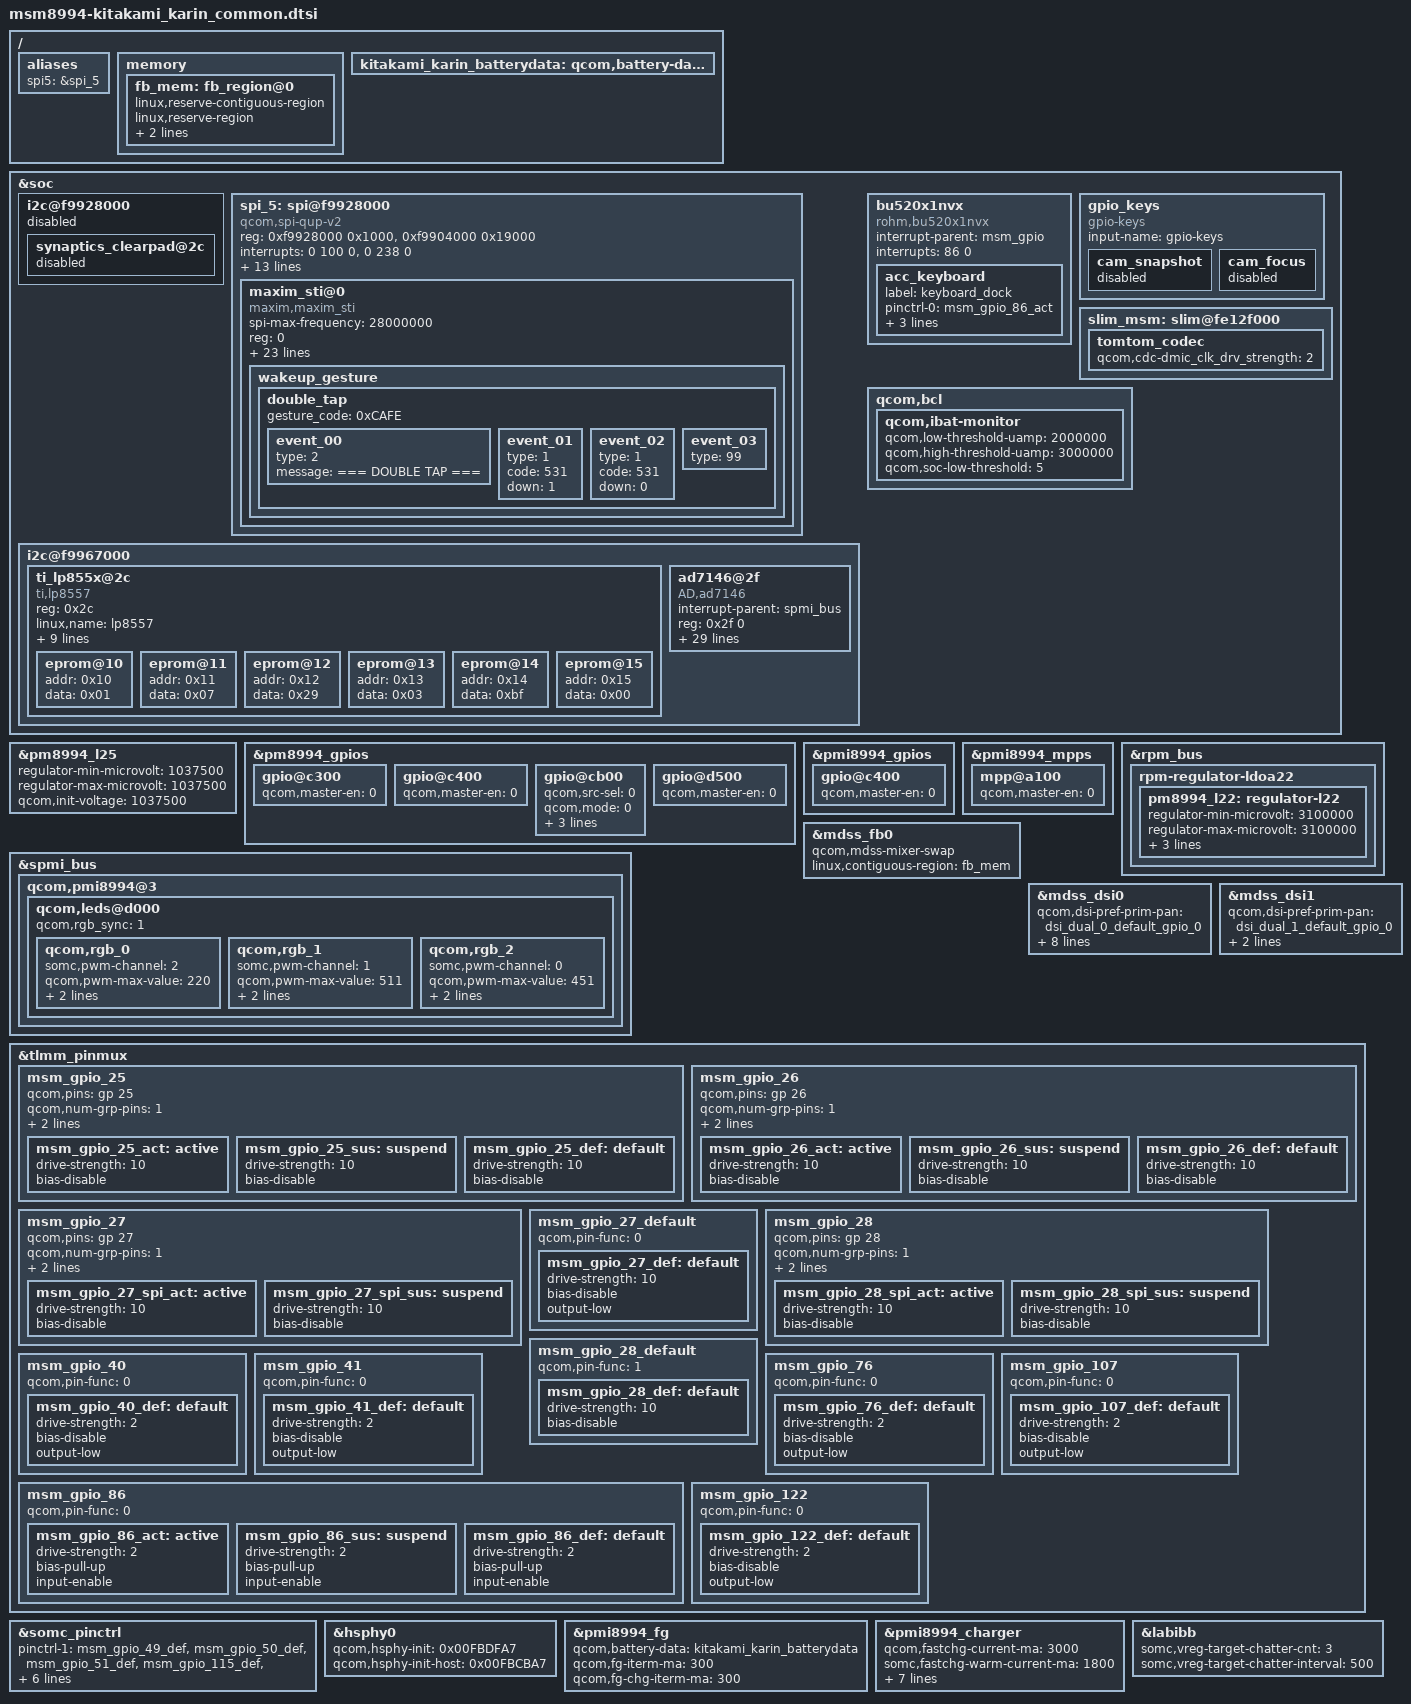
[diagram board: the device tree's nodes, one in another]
/* arch/arm/boot/dts/qcom/msm8994-kitakami_karin_common.dtsi
 *
 * This program is free software; you can redistribute it and/or modify
 * it under the terms of the GNU General Public License version 2 and
 * only version 2 as published by the Free Software Foundation.
 *
 * This program is distributed in the hope that it will be useful,
 * but WITHOUT ANY WARRANTY; without even the implied warranty of
 * MERCHANTABILITY or FITNESS FOR A PARTICULAR PURPOSE.  See the
 * GNU General Public License for more details.
 */
/*
 * Copyright (C) 2014 Sony Mobile Communications Inc.
 *
 * This program is free software; you can redistribute it and/or modify
 * it under the terms of the GNU General Public License version 2, as
 * published by the Free Software Foundation.
 */

/ {
	aliases {
		spi5 = &spi_5;
	};

	memory {

		fb_mem: fb_region@0 {
			linux,reserve-contiguous-region;
			linux,reserve-region;
			reg = <0 0x40000000 0 0x2000000>;
			label = "fb_mem";
		};
	};
};

&soc {
	i2c@f9928000 {
		status = "disabled";
		synaptics_clearpad@2c {
			status = "disabled";
		};
	};

	/* SPI : BLSP6 */
	spi_5: spi@f9928000 {
		compatible = "qcom,spi-qup-v2";
		#address-cells = <1>;
		#size-cells = <0>;
		reg-names = "spi_physical", "spi_bam_physical";
		reg = <0xf9928000 0x1000>, <0xf9904000 0x19000>;
		interrupt-names = "spi_irq", "spi_bam_irq";
		interrupts = <0 100 0>, <0 238 0>;
		spi-max-frequency = <48000000>;
		qcom,use-bam;
		qcom,ver-reg-exists;
		qcom,bam-consumer-pipe-index = <22>;
		qcom,bam-producer-pipe-index = <23>;
		qcom,master-id = <86>;

		qcom,use-pinctrl;
		pinctrl-names = "default", "sleep";
		pinctrl-0 = <&msm_gpio_25_act &msm_gpio_26_act &msm_gpio_27_spi_act &msm_gpio_28_spi_act>;
		pinctrl-1 = <&msm_gpio_25_sus &msm_gpio_26_sus &msm_gpio_27_spi_sus &msm_gpio_28_spi_sus>;

		clock-names = "iface_clk", "core_clk";
		clocks = <&clock_gcc clk_gcc_blsp1_ahb_clk>,
			 <&clock_gcc clk_gcc_blsp1_qup6_spi_apps_clk>;

		status = "ok";

		maxim_sti@0 {
			compatible = "maxim,maxim_sti";
			spi-max-frequency = <28000000>;
			reg = <0>;
			interrupt-parent = <&msm_gpio>;
			interrupts = <42 0x2>;
			avdd-supply = <&pm8994_l22>;
			dvdd-supply = <&pm8994_s4>;
			mode = <0>;
			maxim_sti,irq-gpio = <&msm_gpio 42 0x00>;
			maxim_sti,reset-gpio = <&msm_gpio 109 0x00>;
			maxim_sti,touch_fusion = "/system/vendor/bin/touch_fusion";
			maxim_sti,config_file = "/system/vendor/etc/touch_fusion_panel_id_0x%04X.cfg";
			maxim_sti,fw_name = "maxim_fp35.bin";
			maxim_sti,nl_family = "touch_fusion";
			maxim_sti,nl_mc_groups = <5>;
			maxim_sti,chip_access_method = <1>;
			maxim_sti,default_reset_state = <0>;
			maxim_sti,tx_buf_size = <4100>;
			maxim_sti,rx_buf_size = <4100>;
			pinctrl-names = "irq_gpio-active", "irq_gpio-suspend",
					"reset_gpio-active", "reset_gpio-suspend";
			pinctrl-0 = <&msm_gpio_42_act>;
			pinctrl-1 = <&msm_gpio_42_sus>;
			pinctrl-2 = <&msm_gpio_109_act>;
			pinctrl-3 = <&msm_gpio_109_sus>;
			wakeup_gesture_support = <1>;
			wakeup_gesture {
				double_tap {
					gesture_code = <0xCAFE>;
					event_00 {
						type = <2>; /* LOG */
						message = "=== DOUBLE TAP ===";
					};
					event_01 {
						type = <1>; /* KEY */
						code = <531>; /* TOUCHPAD_ON */
						down = <1>;
					};
					event_02 {
						type = <1>; /* KEY */
						code = <531>; /* TOUCHPAD_ON */
						down = <0>;
					};
					event_03 {
						type = <99>; /* END */
					};
				};
			};
		};
	};

	/* I2C : BLSP11 */
	i2c@f9967000 {
		status = "ok";
		ti_lp855x@2c {
			compatible = "ti,lp8557";
			reg = <0x2c>;
			status = "ok";
			linux,name = "lp8557";
			linux,default-trigger = "bkl-trigger";
			mode = "register based";
			chip_name = "lp8557";
			max_br = <0xFF>;
			init_br = <0x83>;
			somc-s1,br-power-save = <0x83>;
			slope_reg = <0x00>;
			dev-ctrl = <0x01>;
			pwm-period = <0x00>;
			eprom@10 {
				addr = <0x10>;
				data = <0x01>;
			};
			eprom@11 {
				addr = <0x11>;
				data = <0x07>;
			};
			eprom@12 {
				addr = <0x12>;
				data = <0x29>;
			};
			eprom@13 {
				addr = <0x13>;
				data = <0x03>;
			};
			eprom@14 {
				addr = <0x14>;
				data = <0xbf>;
			};
			eprom@15 {
				addr = <0x15>;
				data = <0x00>;
			};
		};

		ad7146@2f {
			compatible = "AD,ad7146";
			interrupt-parent = <&spmi_bus>;
			reg = <0x2f 0>;
			interrupts = <0x0 0xcb 0x0>; /* PM8994 GPIO 12 */
			interrupt-name = "ad7146_irq_gpio";
			prox_vdd-supply = <&pm8994_l19>;
			prox_vdd-supply_name = "prox_vdd";
			AD,irq_gpio = <&pm8994_gpios 12 0x00>;
			pad,amb_comp_ctrl0 = <0x00FB>;
			pad,amb_comp_ctrl1 = <0x0401>;
			pad,amb_comp_ctrl2 = <0x04F0>;
			pad,mod_freq_ctrl = <0x0D00>;
			pad,stage0-connect1 = <0x3B7F>;
			pad,stage0-connect2 = <0x1FFF>;
			pad,stage0-afe = <0x0003>;
			pad,stage0-sensitivity = <0x5454>;
			pad,stage0-offset_l = <0x000A>;
			pad,stage0-offset_h = <0x0070>;
			pad,stage0-offset_l_clamp = <0x000A>;
			pad,stage0-offset_h_clamp = <0x0070>;
			pad,stage0-hysterisis = <10>;
			pad,stage0-high_th_offset = <50>;
			pad,stage1-connect1 = <0x3FFF>;
			pad,stage1-connect2 = <0x06FF>;
			pad,stage1-afe = <0x0500>;
			pad,stage1-sensitivity = <0x5454>;
			pad,stage1-offset_l = <0x000A>;
			pad,stage1-offset_h = <0x0070>;
			pad,stage1-offset_l_clamp = <0x000A>;
			pad,stage1-offset_h_clamp = <0x0070>;
			pad,stage1-hysterisis = <15>;
			pad,stage1-high_th_offset = <50>;
			status = "ok";
		};
	};

	bu520x1nvx {
		compatible = "rohm,bu520x1nvx";
		interrupt-parent = <&msm_gpio>;
		interrupts = <86 0>;

		acc_keyboard {
			label = "keyboard_dock";
			pinctrl-names = "bu520x1nvx_active",
					"bu520x1nvx_suspend";
			pinctrl-0 = <&msm_gpio_86_act>;
			pinctrl-1 = <&msm_gpio_86_sus>;
			gpios = <&msm_gpio 86 0x1>;
			debounce-interval = <100>;
		};
	};

	gpio_keys {
		compatible = "gpio-keys";
		input-name = "gpio-keys";

		cam_snapshot {
			status = "disabled";
		};

		cam_focus {
			status = "disabled";
		};
	};

	slim_msm: slim@fe12f000 {
		tomtom_codec {
			qcom,cdc-dmic_clk_drv_strength = <2>;
		};
	};

	qcom,bcl {
		qcom,ibat-monitor {
			qcom,low-threshold-uamp = <2000000>;
			qcom,high-threshold-uamp = <3000000>;
			qcom,soc-low-threshold = <5>;
		};
	};
};

&pm8994_l22 {
	qcom,init-enable = <1>;
	qcom,send-defaults;
};

&pm8994_l25 {
	regulator-min-microvolt = <1037500>;
	regulator-max-microvolt = <1037500>;
	qcom,init-voltage = <1037500>;
};

&pm8994_gpios {
	/* GPIO_4: NC */
	gpio@c300 {
		qcom,master-en = <0>;		/* Disable */
		status = "ok";
	};

	/* GPIO_5: NC */
	gpio@c400 {
		qcom,master-en = <0>;		/* Disable */
		status = "ok";
	};

	/* GPIO_12: P_SENSE_INT_N */
	gpio@cb00 {
		qcom,src-sel = <0>;		/* GPIO */
		qcom,mode = <0>;		/* In */
		qcom,vin-sel = <2>;		/* S4 */
		qcom,pull = <0>;		/* PU */
		qcom,master-en = <1>;		/* Enable */
		status = "ok";
	};

	/* GPIO_22: NC */
	gpio@d500 {
		qcom,master-en = <0>;		/* Disable */
		status = "ok";
	};
};

&pmi8994_gpios {
	/* GPIO_5: NC */
	gpio@c400 {
		qcom,master-en = <0>;		/* Disable */
		status = "ok";
	};
};

&pmi8994_mpps {
	/* MPP_2: NC */
	mpp@a100 {
		qcom,master-en = <0>;		/* Disable */
		status = "ok";
	};
};

&rpm_bus {
	rpm-regulator-ldoa22 {
		status = "okay";
		pm8994_l22: regulator-l22 {
			regulator-min-microvolt = <3100000>;
			regulator-max-microvolt = <3100000>;
			qcom,init-voltage = <3100000>;
			status = "okay";
		};
	};
};

&spmi_bus {
	qcom,pmi8994@3 {
		qcom,leds@d000 {
			status = "okay";
			qcom,rgb_sync = <1>;

			qcom,rgb_0 {
				somc,pwm-channel = <2>;
				qcom,pwm-max-value = <220>;
				linux,name = "led:rgb_red";
				linux,default-trigger = "none";
			};
			qcom,rgb_1 {
				somc,pwm-channel = <1>;
				qcom,pwm-max-value = <511>;
				linux,name = "led:rgb_green";
				linux,default-trigger = "none";
			};
			qcom,rgb_2 {
				somc,pwm-channel = <0>;
				qcom,pwm-max-value = <451>;
				linux,name = "led:rgb_blue";
				linux,default-trigger = "none";
			};
		};
	};
};

&mdss_fb0 {
	qcom,mdss-mixer-swap;
	linux,contiguous-region = <&fb_mem>;
};

&mdss_dsi0 {
	qcom,dsi-pref-prim-pan = <&dsi_dual_0_default_gpio_0>;
	pinctrl-names = "mdss_default", "mdss_sleep";
	pinctrl-0 = <&msm_gpio_10_act &msm_gpio_56_act &msm_gpio_78_act>;
	pinctrl-1 = <&msm_gpio_10_sus &msm_gpio_56_sus &msm_gpio_78_sus>;
	qcom,dsi-panel-bias-vreg;
	qcom,platform-reset-gpio = <&msm_gpio 78 0>;
	qcom,platform-regulator-settings = [];
	qcom,platform-lane-config = [];
};

&mdss_dsi1 {
	qcom,dsi-pref-prim-pan = <&dsi_dual_1_default_gpio_0>;
	qcom,platform-regulator-settings = [];
	qcom,platform-lane-config = [];
};

&tlmm_pinmux {
	/* GPIO_25: TS_SPI_MOSI */
	msm_gpio_25 {
		qcom,pins = <&gp 25 >;
		qcom,num-grp-pins = <1>;
		label = "msm_gpio_25 ";
		qcom,pin-func = <3>;
		msm_gpio_25_act: active {
			drive-strength = <10>;
			bias-disable;
		};
		msm_gpio_25_sus: suspend {
			drive-strength = <10>;
			bias-disable;
		};
		msm_gpio_25_def: default {
			drive-strength = <10>;
			bias-disable;
			/delete-property/ output-low;
		};
	};

	/* GPIO_26: TS_SPI_MISO */
	msm_gpio_26 {
		qcom,pins = <&gp 26>;
		qcom,num-grp-pins = <1>;
		label = "msm_gpio_26";
		qcom,pin-func = <2>;
		msm_gpio_26_act: active {
			drive-strength = <10>;
			bias-disable;
		};
		msm_gpio_26_sus: suspend {
			drive-strength = <10>;
			bias-disable;
		};
		msm_gpio_26_def: default {
			drive-strength = <10>;
			bias-disable;
			/delete-property/ output-low;
		};
	};

	/* GPIO_27: TS_SPI_CS_N */
	msm_gpio_27 {
		qcom,pins = <&gp 27>;
		qcom,num-grp-pins = <1>;
		label = "msm_gpio_27";
		qcom,pin-func = <1>;
		msm_gpio_27_spi_act: active {
			drive-strength = <10>;
			bias-disable;
		};
		msm_gpio_27_spi_sus: suspend {
			drive-strength = <10>;
			bias-disable;
		};
	};
	msm_gpio_27_default {
		qcom,pin-func = <0>;
		msm_gpio_27_def: default {
			drive-strength = <10>;
			bias-disable;
			output-low;
		};
	};

	/* GPIO_28: TS_SPI_CLK */
	msm_gpio_28 {
		qcom,pins = <&gp 28>;
		qcom,num-grp-pins = <1>;
		label = "msm_gpio_28";
		qcom,pin-func = <1>;
		msm_gpio_28_spi_act: active {
			drive-strength = <10>;
			bias-disable;
		};
		msm_gpio_28_spi_sus: suspend {
			drive-strength = <10>;
			bias-disable;
		};
	};
	msm_gpio_28_default {
		qcom,pin-func = <1>;
		msm_gpio_28_def: default {
			drive-strength = <10>;
			bias-disable;
		};
	};

	/* GPIO_40: NC */
	msm_gpio_40 {
		qcom,pin-func = <0>;
		msm_gpio_40_def: default {
			drive-strength = <2>;
			bias-disable;
			output-low;
			/delete-property/ input-enable;
		};
	};

	/* GPIO_41: NC */
	msm_gpio_41 {
		qcom,pin-func = <0>;
		msm_gpio_41_def: default {
			drive-strength = <2>;
			bias-disable;
			output-low;
			/delete-property/ bias-pull-up;
			/delete-property/ input-enable;
		};
	};

	/* GPIO_76: NC */
	msm_gpio_76 {
		qcom,pin-func = <0>;
		msm_gpio_76_def: default {
			drive-strength = <2>;
			bias-disable;
			output-low;
			/delete-property/ bias-pull-down;
			/delete-property/ input-enable;
		};
	};

	/* GPIO_86: EXT_KEYBRD_DET */
	msm_gpio_86 {
		qcom,pin-func = <0>;
		msm_gpio_86_act: active {
			drive-strength = <2>;
			bias-pull-up;
			input-enable;
		};
		msm_gpio_86_sus: suspend {
			drive-strength = <2>;
			bias-pull-up;
			input-enable;
		};
		msm_gpio_86_def: default {
			drive-strength = <2>;
			bias-pull-up;
			input-enable;
			/delete-property/ bias-disable;
			/delete-property/ output-low;
		};
	};

	/* GPIO_107: NC */
	msm_gpio_107 {
		qcom,pin-func = <0>;
		msm_gpio_107_def: default {
			drive-strength = <2>;
			bias-disable;
			output-low;
		};
	};

	/* GPIO_122: NC */
	msm_gpio_122 {
		qcom,pin-func = <0>;
		msm_gpio_122_def: default {
			drive-strength = <2>;
			bias-disable;
			output-low;
		};
	};
};

&somc_pinctrl {
	pinctrl-1 = <&msm_gpio_49_def &msm_gpio_50_def &msm_gpio_51_def &msm_gpio_115_def &msm_gpio_116_def
		     &msm_gpio_117_def &msm_gpio_118_def &msm_gpio_120_def &msm_gpio_121_def &msm_gpio_124_def
		     &msm_gpio_126_def &msm_gpio_127_def &msm_gpio_130_def &msm_gpio_132_def &msm_gpio_133_def
		     &msm_gpio_143_def>;
};

&hsphy0 {
	qcom,hsphy-init = <0x00FBDFA7>;
	qcom,hsphy-init-host = <0x00FBCBA7>;
};

/{
	kitakami_karin_batterydata: qcom,battery-data {
		#include "batterydata-kitakami-karin-send.dtsi"
	};
};

&pmi8994_fg {
	qcom,battery-data = <&kitakami_karin_batterydata>;
	qcom,fg-iterm-ma = <300>;
	qcom,fg-chg-iterm-ma = <300>;
};

&pmi8994_charger {
	qcom,fastchg-current-ma = <3000>;
	somc,fastchg-warm-current-ma = <1800>;
	somc,fastchg-cool-current-ma = <1800>;
	qcom,iterm-ma = <300>;
	qcom,precharging-timeout-mins = <24>;
	qcom,charging-timeout-mins = <768>;
	somc,thermal-engine-fastchg-current = <3000 2500 2000 1500 1200 900 600 450 300 300 300 300 300 300 0>;
	somc,usb-9v-current-max = <1600>;
};

&labibb {
	somc,vreg-target-chatter-cnt = <3>;
	somc,vreg-target-chatter-interval = <500>;
};
